# PCIE1_CORE_DBN_CFG_PCIE_CORE register map
Vendor: Texas Instruments
Peripheral module from a debugger description file (folder J7VCL).
Registers are 32-bit, read-write, reset values left out (the file's numbers can be read two ways) unless marked. A register's access mark holds for its fields unless they carry their own. Offsets are as the file gives them; lines under a group give offsets from that group; [hi:lo] are bit positions; {n}, {i} and the like mark numbered series; 'fields as' and 'values as' point back to an identical list; <NAME> marks a mode.

## PCIE1_CORE_DBN_CFG_PCIE_CORE
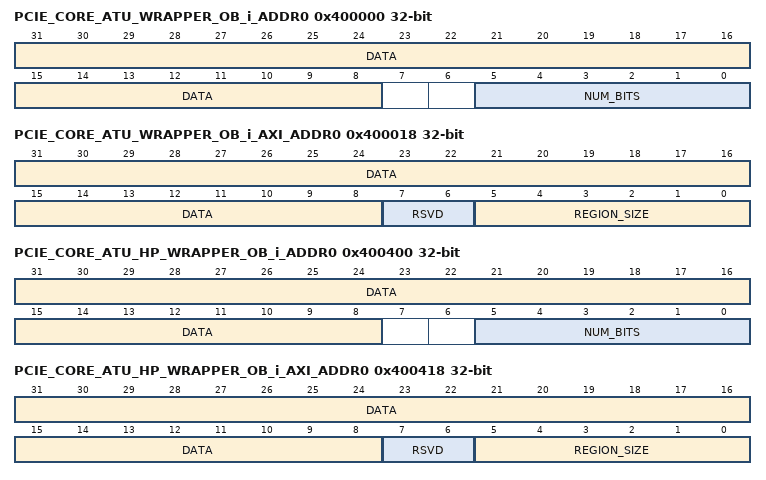
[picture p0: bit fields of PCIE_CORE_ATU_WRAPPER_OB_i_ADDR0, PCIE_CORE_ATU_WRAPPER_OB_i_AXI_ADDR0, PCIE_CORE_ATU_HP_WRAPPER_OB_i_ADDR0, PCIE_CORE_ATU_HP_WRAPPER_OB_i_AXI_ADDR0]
0x400000 PCIE_CORE_ATU_WRAPPER_OB_i_ADDR0 access per field — Return to the . Provides bits 31:8 of the PCIe address and the number of AXI address bits passed through Offset = 400000h + (i * 20h); where i = 0h to 1Fh
  [31:8] DATA rw — Bits[31:8] of PCIe Address Register for region N
  [5:0] NUM_BITS rw — Number_bits + 1 bits are passed through from AXI address to the PCIe address
0x400004 PCIE_CORE_ATU_WRAPPER_OB_i_ADDR1 — Return to the . Provides bits 63:32 of the PCIe address Offset = 400004h + (i * 20h); where i = 0h to 1Fh
  [31:0] DATA — Bits [63:32] of PCIe Address Register for region N
0x400008 PCIE_CORE_ATU_WRAPPER_OB_i_DESC0 — Return to the . Provides bits 31:0 of the Outbound PCIe Descriptor Offset = 400008h + (i * 20h); where i = 0h to 1Fh
  [31:0] DATA — Lowest 32-bits of PCIe Descriptor Register for region N
0x40000C PCIE_CORE_ATU_WRAPPER_OB_i_DESC1 — Return to the . Provides bits 63:32 of the PCIe Descriptor Offset = 40000Ch + (i * 20h); where i = 0h to 1Fh
  [31:0] DATA — Lower middle 32-bits of PCIe Descriptor Register for region N
0x400014 PCIE_CORE_ATU_WRAPPER_OB_i_DESC3 access per field — Return to the . Provides PASID Value and The present bit Offset = 400014h + (i * 20h); where i = 0h to 1Fh
  [22:0] DATA rw — {Execute Permission Supported, Privileged Mode Supported, PASID Value, PASID present bit}
0x400018 PCIE_CORE_ATU_WRAPPER_OB_i_AXI_ADDR0 — Return to the . holds the base address [31:8] of this region. Lower [5:0] is used for region size programmability Offset = 400018h + (i * 20h); where i = 0h to 1Fh
  [31:8] DATA — Bits[31:8] of Outbound AXI Region Base Address Register used to decode the region
  [7:6] RSVD — These needs to be forced to 0
  [5:0] REGION_SIZE — the value programmed in this field + 1 gives the region size
0x40001C PCIE_CORE_ATU_WRAPPER_OB_i_AXI_ADDR1 — Return to the . holds the base address [63:32] of this region. Offset = 40001Ch + (i * 20h); where i = 0h to 1Fh
  [31:0] DATA — Bits [63:32] of AXI outbound Base Address Register used to decode the region
0x400400 PCIE_CORE_ATU_HP_WRAPPER_OB_i_ADDR0 access per field — Return to the . Provides bits 31:8 of the PCIe address and the number of AXI address bits passed through Offset = 400400h + (i * 20h); where i = 0h to 1Fh
  fields as PCIE_CORE_ATU_WRAPPER_OB_i_ADDR0
0x400404 PCIE_CORE_ATU_HP_WRAPPER_OB_i_ADDR1 — Return to the . Provides bits 63:32 of the PCIe address Offset = 400404h + (i * 20h); where i = 0h to 1Fh
  [31:0] DATA — Bits [63:32] of PCIe Address Register for region N
0x400408 PCIE_CORE_ATU_HP_WRAPPER_OB_i_DESC0 — Return to the . Provides bits 31:0 of the Outbound PCIe Descriptor Offset = 400408h + (i * 20h); where i = 0h to 1Fh
  fields as PCIE_CORE_ATU_WRAPPER_OB_i_DESC0
0x40040C PCIE_CORE_ATU_HP_WRAPPER_OB_i_DESC1 — Return to the . Provides bits 63:32 of the PCIe Descriptor Offset = 40040Ch + (i * 20h); where i = 0h to 1Fh
  fields as PCIE_CORE_ATU_WRAPPER_OB_i_DESC1
0x400414 PCIE_CORE_ATU_HP_WRAPPER_OB_i_DESC3 access per field — Return to the . Provides PASID Value and The present bit Offset = 400414h + (i * 20h); where i = 0h to 1Fh
  fields as PCIE_CORE_ATU_WRAPPER_OB_i_DESC3
0x400418 PCIE_CORE_ATU_HP_WRAPPER_OB_i_AXI_ADDR0 — Return to the . Holds the base address [31:8] of this region. Lower [5:0] is used for region size programmability Offset = 400418h + (i * 20h); where i = 0h to 1Fh
  fields as PCIE_CORE_ATU_WRAPPER_OB_i_AXI_ADDR0
0x40041C PCIE_CORE_ATU_HP_WRAPPER_OB_i_AXI_ADDR1 — Return to the . holds the base address [63:32] of this region. Offset = 40041Ch + (i * 20h); where i = 0h to 1Fh
  fields as PCIE_CORE_ATU_WRAPPER_OB_i_AXI_ADDR1
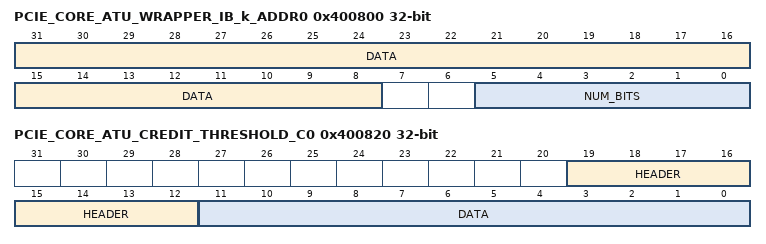
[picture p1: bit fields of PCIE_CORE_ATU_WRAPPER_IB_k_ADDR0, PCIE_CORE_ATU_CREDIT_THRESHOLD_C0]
0x400800 PCIE_CORE_ATU_WRAPPER_IB_k_ADDR0 access per field — Return to the . Provides bits 31:8 of the AXI Address and the number of PCIE address bits passed through Offset = 400800h + (k * 8h); where k = 0h to 2h
  [31:8] DATA rw — Bits [31:8] of AXI Address Register for BAR N
  [5:0] NUM_BITS rw — The value programmed in this register +1 bits are passed through from PCIe to AXI
0x400804 PCIE_CORE_ATU_WRAPPER_IB_k_ADDR1 — Return to the . Provides bits 63:32 of the AXI Address Offset = 400804h + (k * 8h); where k = 0h to 2h
  [31:0] DATA — Bits [63:32] of AXI Address Register for BAR N
0x400820 PCIE_CORE_ATU_CREDIT_THRESHOLD_C0 — Return to the . N/A
  [19:12] HEADER — This is the threshold value of the header credits required which is used to flag credit availability in AXI wrapper
  [11:0] DATA — This is the threshold value of the payload credits required which is used to flag credit availability in AXI wrapper
0x400824 PCIE_CORE_ATU_LINK_DOWN_INDICATOR_BIT_L0 — Return to the . N/A
  [0] CLEAR_LINK_DOWN_BIT_TO_PROCEED — This bit will be set when link down reset comes.client should clear this bit before issueing new traffic to the core
0x400840 PCIE_CORE_ATU_FUNCm_WRAPPER_IB_EP_n_ADDR0 — Return to the . Provides bits 31:0 of the AXI address Offset = 400840h + (m * 40h) + (n * 8h); where m = 0 to 15h, n = 0h to 7h
  [31:0] DATA — Bits [31:0] of Address Register for BAR N
0x400844 PCIE_CORE_ATU_FUNCm_WRAPPER_IB_EP_n_ADDR1 — Return to the . Provides bits 63:32 of the AXI address Offset = 400844h + (m * 40h) + (n * 8h); where m = 0 to 15h, n = 0h to 7h
  [31:0] DATA — Bits [63:32] of AXI Address Register for BAR N
